# ESP32-H21 register map
Vendor: ESPRESSIF SYSTEMS (SHANGHAI) CO., LTD.; Series: ESP32 H-Series; File version: 1
CPU: RV32IMAC r0p0, little endian, no MPU, no FPU, 0 interrupt priority bits
Address unit: 32 bits
Registers are 32-bit, read-write, reset 0x0 unless marked. A register's access mark holds for its fields unless they carry their own. Offsets are from the block's base; [hi:lo] are bit positions; {n}, {i} and the like mark numbered series.

## I2C_ANA_MST — I2C_ANA_MST Peripheral
Base 0x600AD800
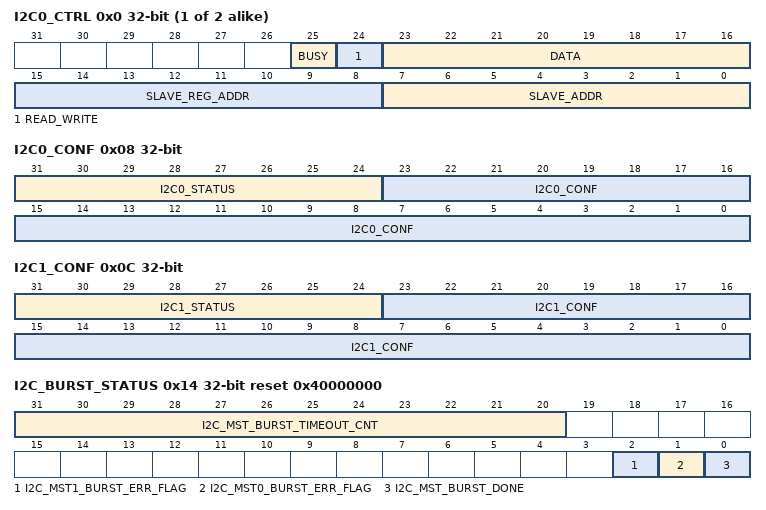
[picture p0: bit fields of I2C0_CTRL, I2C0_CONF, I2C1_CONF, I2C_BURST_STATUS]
{0x0+4i} I2C{i}_CTRL (i=0..1) — I2C{i}_CTRL
  [25] BUSY ro, [24] READ_WRITE, [23:16] DATA, [15:8] SLAVE_REG_ADDR, [7:0] SLAVE_ADDR
0x08 I2C0_CONF
  [31:24] I2C0_STATUS ro, [23:0] I2C0_CONF
0x0C I2C1_CONF
  [31:24] I2C1_STATUS ro, [23:0] I2C1_CONF
0x10 I2C_BURST_CONF
  [31:0] I2C_MST_BURST_CTRL
0x14 I2C_BURST_STATUS reset 0x40000000
  [31:20] I2C_MST_BURST_TIMEOUT_CNT, [2] I2C_MST1_BURST_ERR_FLAG, [1] I2C_MST0_BURST_ERR_FLAG, [0] I2C_MST_BURST_DONE
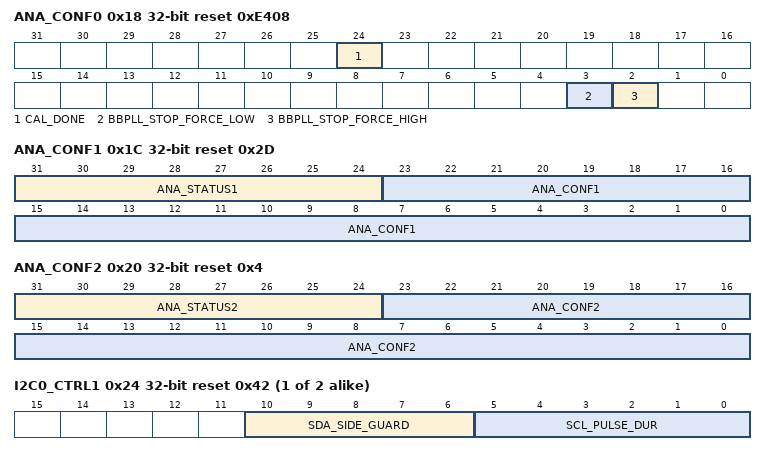
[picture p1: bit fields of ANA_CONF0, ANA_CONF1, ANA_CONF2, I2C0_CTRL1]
0x18 ANA_CONF0 reset 0xE408
  [24] CAL_DONE ro — BBPLL calibration done
  [3] BBPLL_STOP_FORCE_LOW — Start the BBPLL calibration
  [2] BBPLL_STOP_FORCE_HIGH — Stop the BBPLL calibration
0x1C ANA_CONF1 reset 0x2D
  [31:24] ANA_STATUS1, [23:0] ANA_CONF1
0x20 ANA_CONF2 reset 0x4
  [31:24] ANA_STATUS2, [23:0] ANA_CONF2
{0x24+4i} I2C{i}_CTRL1 (i=0..1) reset 0x42 — I2C{i}_CTRL1
  [10:6] SDA_SIDE_GUARD, [5:0] SCL_PULSE_DUR
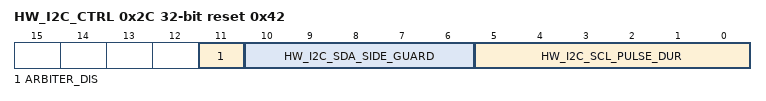
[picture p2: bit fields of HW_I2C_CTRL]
0x2C HW_I2C_CTRL reset 0x42
  [11] ARBITER_DIS, [10:6] HW_I2C_SDA_SIDE_GUARD, [5:0] HW_I2C_SCL_PULSE_DUR
0x30 I2C_MST_NOUSE
0x34 DATE

## LP_CLKRST — LP_CLKRST Peripheral
Base 0x600B0400
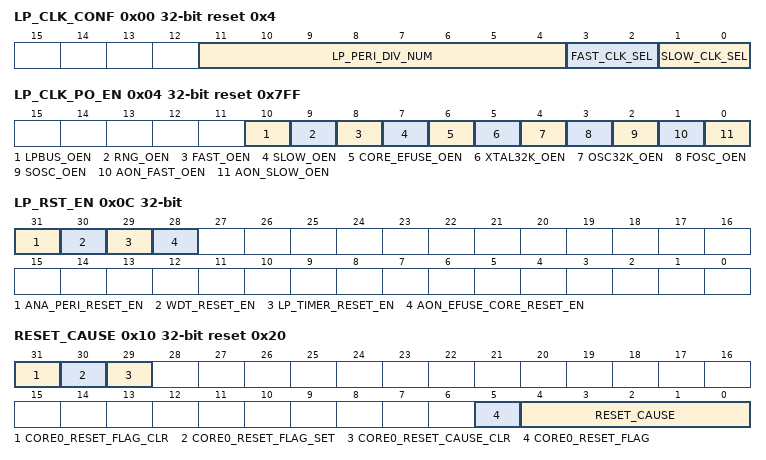
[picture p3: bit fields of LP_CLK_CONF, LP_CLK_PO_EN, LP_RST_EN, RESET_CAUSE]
0x00 LP_CLK_CONF reset 0x4 — need_des
  [11:4] LP_PERI_DIV_NUM — need_des
  [3:2] FAST_CLK_SEL — need_des
  [1:0] SLOW_CLK_SEL — need_des
0x04 LP_CLK_PO_EN reset 0x7FF — need_des
  [10] LPBUS_OEN — need_des
  [9] RNG_OEN — need_des
  [8] FAST_OEN — need_des
  [7] SLOW_OEN — need_des
  [6] CORE_EFUSE_OEN — need_des
  [5] XTAL32K_OEN — need_des
  [4] OSC32K_OEN — need_des
  [3] FOSC_OEN — need_des
  [2] SOSC_OEN — need_des
  [1] AON_FAST_OEN — need_des
  [0] AON_SLOW_OEN — need_des
0x08 LP_CLK_EN — need_des
  [31] FAST_ORI_GATE
0x0C LP_RST_EN — need_des
  [31] ANA_PERI_RESET_EN — need_des
  [30] WDT_RESET_EN — need_des
  [29] LP_TIMER_RESET_EN — need_des
  [28] AON_EFUSE_CORE_RESET_EN — need_des
0x10 RESET_CAUSE access per field reset 0x20 — need_des
  [31] CORE0_RESET_FLAG_CLR wo — need_des
  [30] CORE0_RESET_FLAG_SET wo — need_des
  [29] CORE0_RESET_CAUSE_CLR wo — need_des
  [5] CORE0_RESET_FLAG ro — need_des
  [4:0] RESET_CAUSE ro — need_des
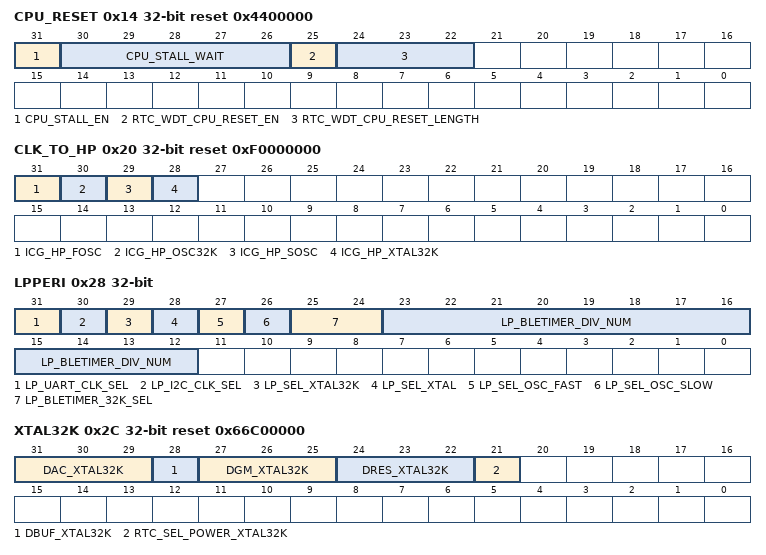
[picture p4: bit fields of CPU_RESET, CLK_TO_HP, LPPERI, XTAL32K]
0x14 CPU_RESET reset 0x4400000 — need_des
  [31] CPU_STALL_EN — need_des
  [30:26] CPU_STALL_WAIT — need_des
  [25] RTC_WDT_CPU_RESET_EN — need_des
  [24:22] RTC_WDT_CPU_RESET_LENGTH — need_des
0x18 FOSC_CNTL reset 0x96000000 — need_des
  [31:22] FOSC_DFREQ
0x1C RC32K_CNTL reset 0xA2800000 — need_des
  [31:22] RC32K_DFREQ
0x20 CLK_TO_HP reset 0xF0000000 — need_des
  [31] ICG_HP_FOSC — need_des
  [30] ICG_HP_OSC32K — need_des
  [29] ICG_HP_SOSC — need_des
  [28] ICG_HP_XTAL32K — need_des
0x24 LPMEM_FORCE — need_des
  [31] LPMEM_CLK_FORCE_ON
0x28 LPPERI — need_des
  [31] LP_UART_CLK_SEL — need_des
  [30] LP_I2C_CLK_SEL — need_des
  [29] LP_SEL_XTAL32K — need_des
  [28] LP_SEL_XTAL — need_des
  [27] LP_SEL_OSC_FAST — need_des
  [26] LP_SEL_OSC_SLOW — need_des
  [25:24] LP_BLETIMER_32K_SEL — need_des
  [23:12] LP_BLETIMER_DIV_NUM — need_des
0x2C XTAL32K reset 0x66C00000 — need_des
  [31:29] DAC_XTAL32K — need_des
  [28] DBUF_XTAL32K — need_des
  [27:25] DGM_XTAL32K — need_des
  [24:22] DRES_XTAL32K — need_des
  [21] RTC_SEL_POWER_XTAL32K — need_des
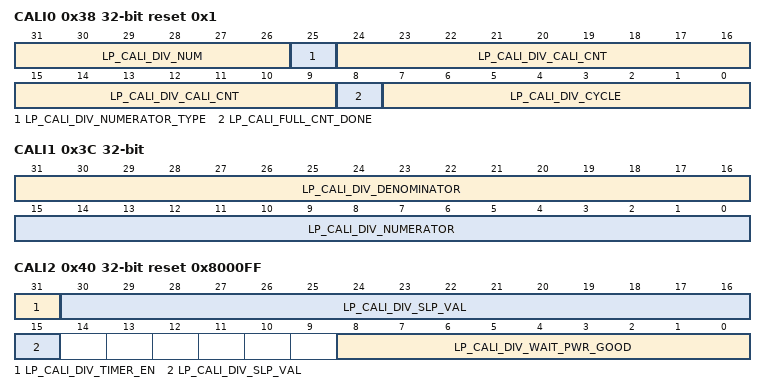
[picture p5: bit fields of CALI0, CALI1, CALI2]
0x38 CALI0 access per field reset 0x1 — LP clock calibration register 0
  [31:26] LP_CALI_DIV_NUM ro, [25] LP_CALI_DIV_NUMERATOR_TYPE ro, [24:9] LP_CALI_DIV_CALI_CNT ro, [8] LP_CALI_FULL_CNT_DONE ro, [7:0] LP_CALI_DIV_CYCLE rw
0x3C CALI1 ro — LP clock calibration register 1
  [31:16] LP_CALI_DIV_DENOMINATOR, [15:0] LP_CALI_DIV_NUMERATOR
0x40 CALI2 reset 0x8000FF — LP clock calibration register 2
  [31] LP_CALI_DIV_TIMER_EN, [30:15] LP_CALI_DIV_SLP_VAL, [8:0] LP_CALI_DIV_WAIT_PWR_GOOD
0x3FC DATE — need_des
